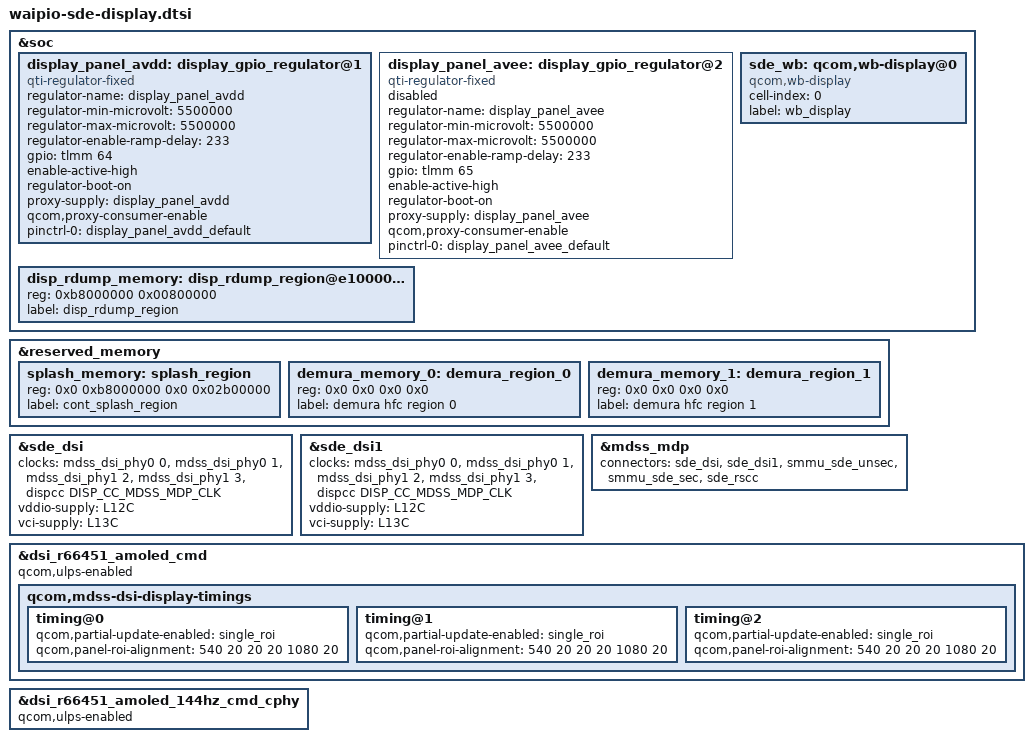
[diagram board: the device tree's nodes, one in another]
// SPDX-License-Identifier: BSD-3-Clause
/*
 * Copyright (c) Qualcomm Technologies, Inc. and/or its subsidiaries.
 */

#include "waipio-sde-display-common.dtsi"
#include <dt-bindings/clock/qcom,sm8450-dispcc.h>

&soc {
	display_panel_avdd: display_gpio_regulator@1 {
		compatible = "qti-regulator-fixed";
		regulator-name = "display_panel_avdd";
		regulator-min-microvolt = <5500000>;
		regulator-max-microvolt = <5500000>;
		regulator-enable-ramp-delay = <233>;
		gpio = <&tlmm 64 0>;
		enable-active-high;
		regulator-boot-on;
		proxy-supply = <&display_panel_avdd>;
		qcom,proxy-consumer-enable;
		pinctrl-names = "default";
		pinctrl-0 = <&display_panel_avdd_default>;
	};

	display_panel_avee: display_gpio_regulator@2 {
		status = "disabled";
		compatible = "qti-regulator-fixed";
		regulator-name = "display_panel_avee";
		regulator-min-microvolt = <5500000>;
		regulator-max-microvolt = <5500000>;
		regulator-enable-ramp-delay = <233>;
		gpio = <&tlmm 65 0>;
		enable-active-high;
		regulator-boot-on;
		proxy-supply = <&display_panel_avee>;
		qcom,proxy-consumer-enable;
		pinctrl-names = "default";
		pinctrl-0 = <&display_panel_avee_default>;
	};

	sde_wb: qcom,wb-display@0 {
		compatible = "qcom,wb-display";
		cell-index = <0>;
		label = "wb_display";
	};

	disp_rdump_memory: disp_rdump_region@e1000000 {
		reg = <0xb8000000 0x00800000>;
		label = "disp_rdump_region";
	};
};

&reserved_memory {
	splash_memory: splash_region {
		reg = <0x0 0xb8000000 0x0 0x02b00000>;
		label = "cont_splash_region";
	};
	/*
	 * Demura memory regions are to be commented out if
	 * feature not in use.
	 */
	demura_memory_0: demura_region_0 {
		reg = <0x0 0x0 0x0 0x0>;
		label = "demura hfc region 0";
	};
	demura_memory_1: demura_region_1 {
		reg = <0x0 0x0 0x0 0x0>;
		label = "demura hfc region 1";
	};
};

&sde_dsi {
	clocks = <&mdss_dsi_phy0 0>,
			<&mdss_dsi_phy0 1>,
			<&mdss_dsi_phy1 2>,
			<&mdss_dsi_phy1 3>,
			 /*
			  * Currently the dsi clock handles are under the dsi
			  * controller DT node. As soon as the controller probe
			  * finishes, the dispcc sync state can get called before
			  * the dsi_display probe potentially disturbing the clock
			  * votes for cont_splash use case. Hence we are no longer
			  * protected by the component model in this case against the
			  * disp cc sync state getting triggered after the dsi_ctrl
			  * probe. To protect against this incorrect sync state trigger
			  * add this dummy MDP clk vote handle to the dsi_display
			  * DT node. Since the dsi_display driver does not parse
			  * MDP clock nodes, no actual vote shall be added and this
			  * change is done just to satisfy sync state requirements.
			  */
			 <&dispcc DISP_CC_MDSS_MDP_CLK>;
	clock-names = "pll_byte_clk0", "pll_dsi_clk0",
			"pll_byte_clk1", "pll_dsi_clk1",
			"mdp_core_clk";

	vddio-supply = <&L12C>;
	vci-supply = <&L13C>;
};

&sde_dsi1 {
	clocks = <&mdss_dsi_phy0 0>,
			<&mdss_dsi_phy0 1>,
			<&mdss_dsi_phy1 2>,
			<&mdss_dsi_phy1 3>,
			 /*
			  * Currently the dsi clock handles are under the dsi
			  * controller DT node. As soon as the controller probe
			  * finishes, the dispcc sync state can get called before
			  * the dsi_display probe potentially disturbing the clock
			  * votes for cont_splash use case. Hence we are no longer
			  * protected by the component model in this case against the
			  * disp cc sync state getting triggered after the dsi_ctrl
			  * probe. To protect against this incorrect sync state trigger
			  * add this dummy MDP clk vote handle to the dsi_display
			  * DT node. Since the dsi_display driver does not parse
			  * MDP clock nodes, no actual vote shall be added and this
			  * change is done just to satisfy sync state requirements.
			  */
			 <&dispcc DISP_CC_MDSS_MDP_CLK>;
	clock-names = "pll_byte_clk0", "pll_dsi_clk0",
			"pll_byte_clk1", "pll_dsi_clk1",
			"mdp_core_clk";

	vddio-supply = <&L12C>;
	vci-supply = <&L13C>;
};

&mdss_mdp {
	connectors = <&sde_dsi &sde_dsi1 &smmu_sde_unsec &smmu_sde_sec &sde_rscc>;
};

&dsi_r66451_amoled_cmd {
	qcom,ulps-enabled;
	qcom,mdss-dsi-display-timings {
		timing@0 {
			qcom,partial-update-enabled = "single_roi";
			qcom,panel-roi-alignment = <540 20 20 20 1080 20>;
		};

		timing@1 {
			qcom,partial-update-enabled = "single_roi";
			qcom,panel-roi-alignment = <540 20 20 20 1080 20>;
		};

		timing@2 {
			qcom,partial-update-enabled = "single_roi";
			qcom,panel-roi-alignment = <540 20 20 20 1080 20>;
		};
	};
};


&dsi_r66451_amoled_144hz_cmd_cphy {
	qcom,ulps-enabled;
};
